# SAM9X60D1G_SOM register map
Vendor: Microchip Technology; Series: SAM9X6; File version: 0
Registers are 32-bit, read-write, reset 0x0 unless marked. A register's access mark holds for its fields unless they carry their own. Offsets are from the block's base; [hi:lo] are bit positions; {n}, {i} and the like mark numbered series.

## MPDDRC — AHB Multiport DDR-SDRAM Controller
Base 0xFFFFE800
0x00 MR — Mode Register
  [2:0] MODE — MPDDRC Command Mode
    0=NORMAL_CMD (Normal Mode. Any access to the MPDDRC is decoded normally. To activate this mode, the command must be followed by a write to the DDR-SDRAM.); 1=NOP_CMD (The MPDDRC issues a NOP command when the DDR-SDRAM device is accessed regardless of the cycle. To activate this mode, the command must be followed by a write to the DDR-SDRAM.); 2=PRCGALL_CMD (The MPDDRC issues the All Banks Precharge command when the DDR-SDRAM device is accessed regardless of the cycle. To activate this mode, the command must be followed by a write to the SDRAM.); 3=LMR_CMD (The MPDDRC issues a Load Mode Register command when the DDR-SDRAM device is accessed regardless of the cycle. To activate this mode, the command must be followed by a write to the DDR-SDRAM.); 4=RFSH_CMD (The MPDDRC issues an Autorefresh command when the DDR-SDRAM device is accessed regardless of the cycle. Previously, an All Banks Precharge command must be issued. To activate this mode, the command must be followed by a write to the DDR-SDRAM.); 5=EXT_LMR_CMD (The MPDDRC issues an Extended Load Mode Register command when the SDRAM device is accessed regardless of the cycle. To activate this mode, the command must be followed by a write to the DDR-SDRAM. The write in the DDR-SDRAM must be done in the appropriate bank.); 6=DEEP_MD (Deep Power mode: Access to Deep Powerdown mode)
0x04 RTR — Refresh Timer Register
  [11:0] COUNT — MPDDRC Refresh Timer Count
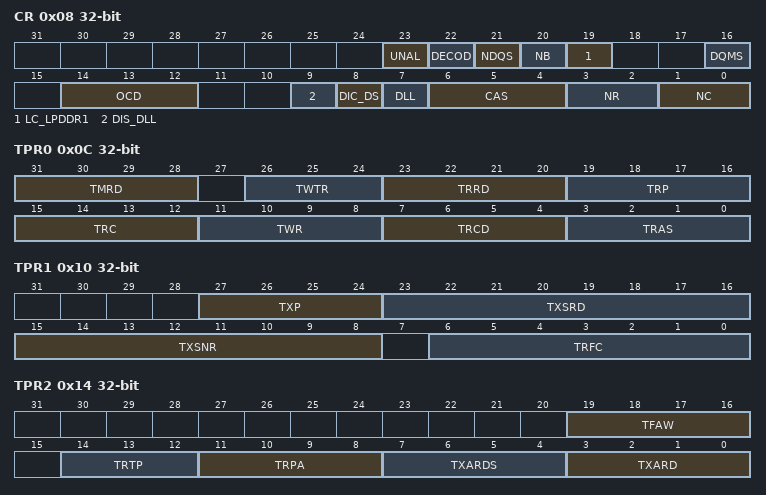
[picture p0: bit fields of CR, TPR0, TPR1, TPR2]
0x08 CR — Configuration Register
  [23] UNAL — This bit must always be written to 1
  [22] DECOD — Type of Decoding
    0=SEQUENTIAL (Method for address mapping where banks alternate at each last DDR-SDRAM page of the current bank.); 1=INTERLEAVED (Method for address mapping where banks alternate at each DDR-SDRAM end of page of the current bank.)
  [21] NDQS — Not DQS.
    0=ENABLED ('Not DQS' is enabled.); 1=DISABLED ('Not DQS' is disabled.)
  [20] NB — Number of Banks
    0=_4_BANKS (4-bank memory devices); 1=_8_BANKS (8 banks. Only possible when using DDR2-SDRAM devices.)
  [19] LC_LPDDR1 — Low-cost Low-power DDR1
    0=NOT_2_BANKS (Any type of memory devices except of low cost, low density Low Power DDR1.); 1=_2_BANKS_LPDDR1 (Low-cost and low-density low-power DDR1. These devices have a density of 32 Mbits and are organized as two internal banks. To use this feature, the user has to define the type of memory and the data bus width (see Section 8.8 'MPDDRC Memory Device Register'). The 16-bit memory device is organized as 2 banks, 9 columns and 11 rows.)
  [16] DQMS — Mask Data is Shared
    0=NOT_SHARED (DQM is not shared with another controller); 1=SHARED (DQM is shared with another controller)
  [14:12] OCD — Off-chip Driver
    0=DDR2_EXITCALIB (Exit from OCD Calibration mode and maintain settings); 7=DDR2_DEFAULT_CALIB (OCD calibration default)
  [9] DIS_DLL — DISABLE DLL
  [8] DIC_DS — Output Driver Impedance Control (Drive Strength)
    0=DDR2_NORMALSTRENGTH (Normal drive strength (DDR2)); 1=DDR2_WEAKSTRENGTH (Weak drive strength (DDR2))
  [7] DLL — Reset DLL
    0=RESET_DISABLED (Disable DLL reset); 1=RESET_ENABLED (Enable DLL reset)
  [6:4] CAS — CAS Latency
    2=DDR_CAS2 (LPDDR1 CAS Latency 2); 3=DDR_CAS3 (DDR2/LPDDR1 CAS Latency 3)
  [3:2] NR — Number of Row Bits.
    0=_11_ROW_BITS (11 bits to define the row number, up to 2048 rows); 1=_12_ROW_BITS (12 bits to define the row number, up to 4096 rows); 2=_13_ROW_BITS (13 bits to define the row number, up to 8192 rows); 3=_14_ROW_BITS (14 bits to define the row number, up to 16384 rows)
  [1:0] NC — Number of Column Bits
    0=DDR9_MDDR8_COL_BITS (9 bits to define the column number, up to 512 columns, for DDR2-SDRAM 8 bits to define the column number, up to 256 columns, for LPDDR1-SDRAM); 1=DDR10_MDDR9_COL_BITS (10 bits to define the column number, up to 1024 columns, for DDR2-SDRAM 9 bits to define the column number, up to 512 columns, for LPDDR1-SDRAM); 2=DDR11_MDDR10_COL_BITS (11 bits to define the column number, up to 2048 columns, for DDR2-SDRAM 10 bits to define the column number, up to 1024 columns, for LPDDR1-SDRAM); 3=DDR12_MDDR11_COL_BITS (12 bits to define the column number, up to 4096 columns, for DDR2-SDRAM 11 bits to define the column number, up to 2048 columns, for LPDDR1-SDRAM)
0x0C TPR0 — Timing Parameter 0 Register
  [31:28] TMRD — Load Mode Register Command to Activate or Refresh Command
  [26:24] TWTR — Internal Write to Read Delay
  [23:20] TRRD — Active BankA to Active BankB
  [19:16] TRP — Row Precharge Delay
  [15:12] TRC — Row Cycle Delay
  [11:8] TWR — Write Recovery Delay
  [7:4] TRCD — Row to Column Delay
  [3:0] TRAS — Active to Precharge Delay
0x10 TPR1 — Timing Parameter 1 Register
  [27:24] TXP — Exit Powerdown Delay to First Command
  [23:16] TXSRD — Exit Self-refresh Delay to Read Command
  [15:8] TXSNR — Exit Self-refresh Delay to Non-Read Command
  [6:0] TRFC — Row Refresh Cycle
0x14 TPR2 — Timing Parameter 2 Register
  [19:16] TFAW — Four Active Windows
  [14:12] TRTP — Read to Precharge
  [11:8] TRPA — Row Precharge All Delay
  [7:4] TXARDS — Exit Active Power Down Delay to Read Command in Mode 'Slow Exit'
  [3:0] TXARD — Exit Active Power Down Delay to Read Command in Mode 'Fast Exit'
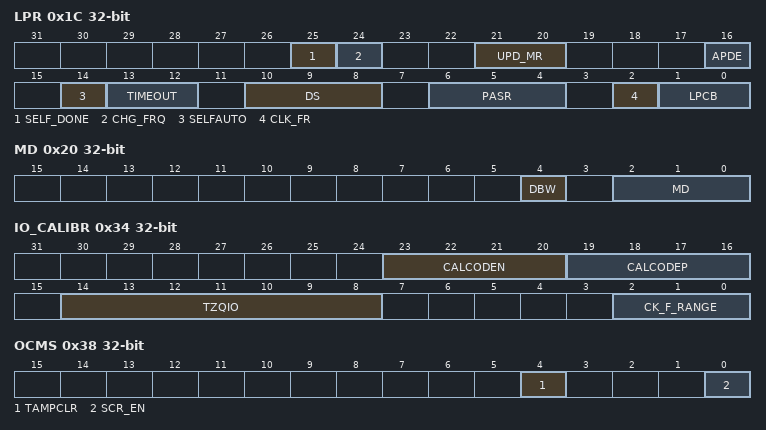
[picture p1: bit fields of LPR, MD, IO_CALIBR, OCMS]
0x1C LPR — Low-Power Register
  [25] SELF_DONE — Self-refresh is Done (read-only)
  [24] CHG_FRQ — Change Clock Frequency During Self-refresh Mode
  [21:20] UPD_MR — Update Load Mode Register and Extended Mode Register
    0=NO_UPDATE (Update of Load Mode and Extended Mode registers is disabled.); 1=UPDATE_SHAREDBUS (MPDDRC shares an external bus. Automatic update is done during a refresh command and a pending read or write access in the SDRAM device.); 2=UPDATE_NOSHAREDBUS (MPDDRC does not share an external bus. Automatic update is done before entering Self-refresh mode.)
  [16] APDE — Active Power Down Exit Time
    0=DDR2_FAST_EXIT (Fast Exit from Power Down. DDR2-SDRAM devices only.); 1=DDR2_SLOW_EXIT (Slow Exit from Power Down. DDR2-SDRAM devices only.)
  [14] SELFAUTO — Self-refresh Exit Autorefresh
  [13:12] TIMEOUT — Time Between Last Transfer and Low-Power Mode
    0=NONE (SDRAM Low-power mode is activated immediately after the end of the last transfer.); 1=DELAY_64_CLK (SDRAM Low-power mode is activated 64 clock cycles after the end of the last transfer.); 2=DELAY_128_CLK (SDRAM Low-power mode is activated 128 clock cycles after the end of the last transfer.)
  [10:8] DS — Drive Strength
    0=DS_FULL (Full drive strength); 1=DS_HALF (Half drive strength); 2=DS_QUARTER (Quarter drive strength); 3=DS_OCTANT (Octant drive strength)
  [6:4] PASR — Partial Array Self-refresh
  [2] CLK_FR — Clock Frozen Command Bit
    0=DISABLED (Clock(s) is/are not frozen.); 1=ENABLED (Clock(s) is/are frozen.)
  [1:0] LPCB — Low-power Command Bit
    0=NOLOWPOWER (Low-power feature is inhibited. No Powerdown, Self-refresh and Deep power modes are issued to the DDR-SDRAM device.); 1=SELFREFRESH (The MPDDRC issues a self-refresh command to the DDR-SDRAM device, the clock(s) is/are deactivated and the CKE signal is set low. The DDR-SDRAM device leaves the Self-refresh mode when accessed and reenters it after the access.); 2=POWERDOWN (The MPDDRC issues a Powerdown command to the DDR-SDRAM device after each access, the CKE signal is set low. The DDR-SDRAM device leaves the Powerdown mode when accessed and reenters it after the access.); 3=DEEPPOWERDOWN (The MPDDRC issues a Deep Powerdown command to the low-power DDR-SDRAM device.)
0x20 MD — Memory Device Register
  [4] DBW — Data Bus Width
    1=DBW_16_BITS (Data bus width is 16 bits.)
  [2:0] MD — Memory Device
    3=LPDDR_SDRAM (Low-power DDR1-SDRAM); 6=DDR2_SDRAM
0x34 IO_CALIBR — I/O Calibration Register
  [23:20] CALCODEN — Number of N-type Transistors (read-only)
  [19:16] CALCODEP — Number of P-type Transistors (read-only)
  [14:8] TZQIO — IO Calibration
  [2:0] CK_F_RANGE — DDRCK Maximum Clock Frequency Range Indicator
0x38 OCMS
  [4] TAMPCLR — Tamper Clear Enable
  [0] SCR_EN — Scrambling Enable
0x3C OCMS_KEY1 wo
  [31:0] KEY1 — Off-chip Memory Scrambling (OCMS) Key Part 1
0x40 OCMS_KEY2 wo
  [31:0] KEY2 — Off-chip Memory Scrambling (OCMS) Key Part 2
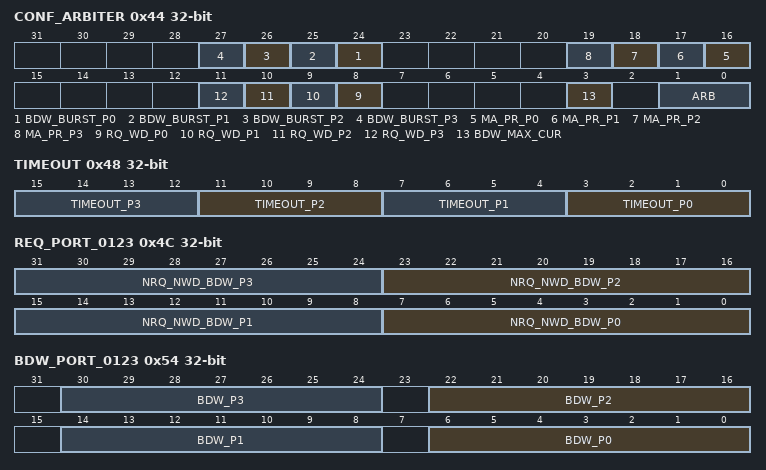
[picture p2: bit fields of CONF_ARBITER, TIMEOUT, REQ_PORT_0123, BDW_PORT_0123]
0x44 CONF_ARBITER — Configuration Arbiter Register
  [n+24] BDW_BURST_P{n} (n=0..3) — Bandwidth Arbitration Mode on Port X
  [n+16] MA_PR_P{n} (n=0..3) — Master or Software Provide Information
  [n+8] RQ_WD_P{n} (n=0..3) — Request or Word from Port X
  [3] BDW_MAX_CUR — Bandwidth Max or Current
  [1:0] ARB — Type of Arbitration
    0=ROUND (Round-Robin Policy); 1=NB_REQUEST (Request Policy); 2=BANDWIDTH (Bandwidth Policy); 3=LQOS (Quality of Service Policy)
0x48 TIMEOUT
  [4n+3:4n] TIMEOUT_P{n} (n=0..3) — Timeout for Ports 0, 1, 2, 3
0x4C REQ_PORT_0123 — Request Port 0-1-2-3 Register
  [8n+7:8n] NRQ_NWD_BDW_P{n} (n=0..3) — Number of Requests, Number of Words or Bandwidth Allocation from Port 0-1-2-3
0x54 BDW_PORT_0123 ro — Current/Maximum Bandwidth Port 0-1-2-3 Register
  [8n+6:8n] BDW_P{n} (n=0..3) — Current/Maximum Bandwidth from Port 0-1-2-3
0x5C RD_DATA_PATH — Read Data Path Register
  [1:0] SHIFT_SAMPLING — Shift Sampling Point of Data
    0=NO_SHIFT (Initial sampling point.); 1=SHIFT_ONE_CYCLE (Sampling point is shifted by one cycle.); 2=SHIFT_TWO_CYCLES (Sampling point is shifted by two cycles.); 3=SHIFT_THREE_CYCLES (Not applicable for DDR2 and LPDDR1 devices.)
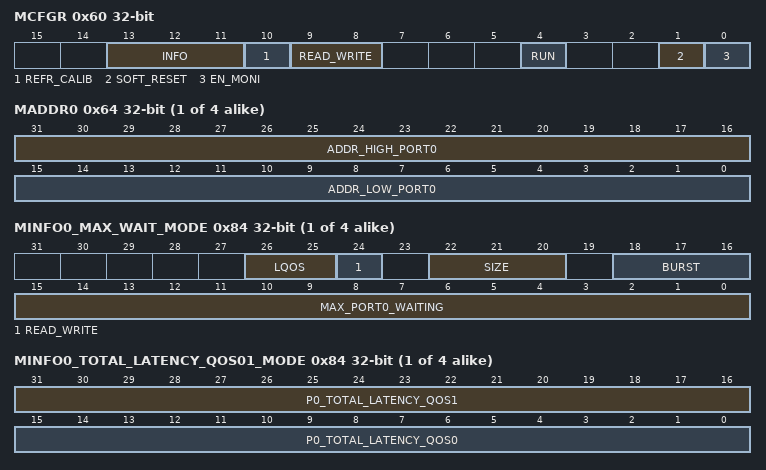
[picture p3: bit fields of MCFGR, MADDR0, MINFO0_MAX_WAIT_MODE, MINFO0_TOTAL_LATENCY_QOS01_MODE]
0x60 MCFGR — Monitor Configuration Register
  [13:11] INFO — Information Type
    0=MAX_WAIT (Information concerning the transfer with the longest waiting time); 1=NB_TRANSFERS (Number of transfers on the port); 2=TOTAL_LATENCY (Total latency on the port); 4=MAX_WAIT_QOS01 (Information concerning the transfer with the longest waiting time, depending on QOS values (0 and 1)); 5=MAX_WAIT_QOS23 (Information concerning the transfer with the longest waiting time, depending on QOS values (2 and 3))
  [10] REFR_CALIB — Refresh Calibration
  [9:8] READ_WRITE — Read/Write Access
    0=TRIG_RD_WR (Read and Write accesses are triggered.); 1=TRIG_WR (Only Write accesses are triggered.); 2=TRIG_RD (Only Read accesses are triggered.)
  [4] RUN — Control Monitor
  [1] SOFT_RESET
  [0] EN_MONI — Enable Monitor
{0x64+4i} MADDR{i} (i=0..3) — Monitor Address High/Low Port {i} Register
  [31:16] ADDR_HIGH_PORT{i} — Address High on Port {i}
  [15:0] ADDR_LOW_PORT{i} — Address Low on Port {i}
{0x84+4i} MINFO{i}_MAX_WAIT_MODE ro (i=0..3) — Monitor Information Port {i} Register
  [26:25] LQOS — Value of Quality Of Service on Port {i}
    0=BACKGROUND (Background transfers); 1=BANDWIDTH (Bandwidth sensitive); 2=SENSITIVE_LAT (Latency sensitive); 3=CRITICAL_LAT (Latency critical)
  [24] READ_WRITE — Read or Write Access on Port {i}
  [22:20] SIZE — Transfer Size on Port {i}
    0=_8BITS (Byte transfer); 1=_16BITS (Halfword transfer); 2=_32BITS (Word transfer); 3=_64BITS (Dword transfer)
  [18:16] BURST — Type of Burst on Port {i}
    0=SINGLE (Single transfer); 1=INCR (Incrementing burst of unspecified length); 2=WRAP4 (4-beat wrapping burst); 3=INCR4 (4-beat incrementing burst); 4=WRAP8 (8-beat wrapping burst); 5=INCR8 (8-beat incrementing burst); 6=WRAP16 (16-beat wrapping burst); 7=INCR16 (16-beat incrementing burst)
  [15:0] MAX_PORT{i}_WAITING — Address High on Port {i}
{0x84+4i} MINFO{i}_NB_TRANSFERS_MODE ro (alternate view of MINFO{i}_MAX_WAIT_MODE) (i=0..3) — Monitor Information Port {i} Register
  [31:0] P{i}_NB_TRANSFERS — Number of Transfers on Port {i}
{0x84+4i} MINFO{i}_TOTAL_LATENCY_MODE ro (alternate view of MINFO{i}_MAX_WAIT_MODE) (i=0..3) — Monitor Information Port {i} Register
  [31:0] P{i}_TOTAL_LATENCY — Total Latency on Port {i}
{0x84+4i} MINFO{i}_TOTAL_LATENCY_QOS01_MODE ro (alternate view of MINFO{i}_MAX_WAIT_MODE) (i=0..3) — Monitor Information Port {i} Register
  [31:16] P{i}_TOTAL_LATENCY_QOS1 — Total Latency on Port 1 when value of qos is 1
  [15:0] P{i}_TOTAL_LATENCY_QOS0 — Total Latency on Port 0 when value of qos is 0
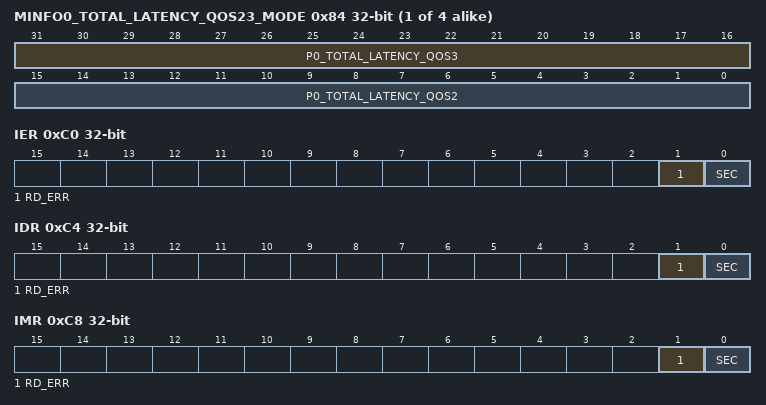
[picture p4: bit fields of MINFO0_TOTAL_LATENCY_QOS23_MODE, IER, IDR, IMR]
{0x84+4i} MINFO{i}_TOTAL_LATENCY_QOS23_MODE ro (alternate view of MINFO{i}_MAX_WAIT_MODE) (i=0..3) — Monitor Information Port {i} Register
  [31:16] P{i}_TOTAL_LATENCY_QOS3 — Total Latency on Port 3 when value of qos is 3
  [15:0] P{i}_TOTAL_LATENCY_QOS2 — Total Latency on Port 2 when value of qos is 2
0xC0 IER wo — Interrupt Enable Register
  [1] RD_ERR — Read Error Interrupt Enable
  [0] SEC — Security and /or Safety Interrupt Enable
0xC4 IDR wo — Interrupt Disable Register
  [1] RD_ERR — Read Error Interrupt Disable
  [0] SEC — Security and /or Safety Interrupt Disable
0xC8 IMR ro — Interrupt Mask Register
  [1] RD_ERR — Read Error Interrupt Mask
  [0] SEC — Security and /or Safety Interrupt Mask
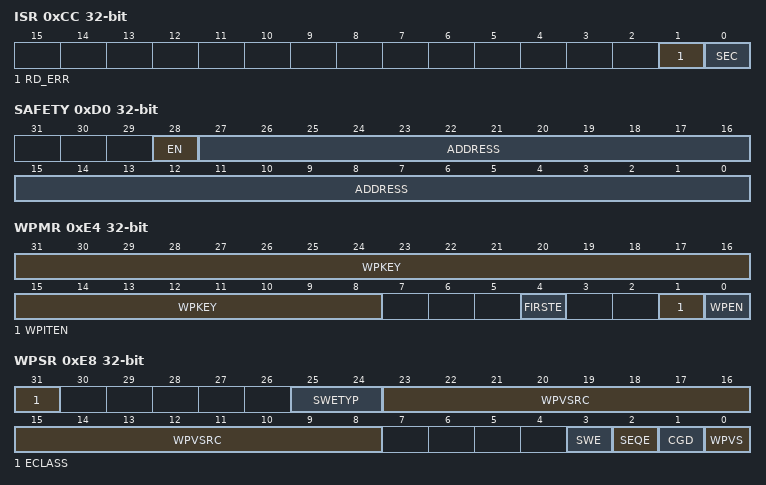
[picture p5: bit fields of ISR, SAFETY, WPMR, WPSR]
0xCC ISR ro — Interrupt Status Register
  [1] RD_ERR — Read Error
  [0] SEC — Security and /or Safety Event
0xD0 SAFETY
  [28] EN — Enable Periodic Check of Memory Device
  [27:0] ADDRESS — Memory Device Address
0xE4 WPMR — Write Protection Mode Register
  [31:8] WPKEY — Write Protection Key
    0x444452=PASSWD (Writing any other value in this field aborts the write operation of the WPEN and WPITEN bits. Always reads as 0.)
  [4] FIRSTE — First Error Report Enable
  [1] WPITEN — Write Protection Interruption Enable
  [0] WPEN — Write Protection Enable
0xE8 WPSR ro — Write Protection Status Register
  [31] ECLASS — Software Error Class (cleared on read)
    0=WARNING (An abnormal access that does not affect system functionality is performed.); 1=ERROR (An access is performed into some registers after memory device initialization sequence.)
  [25:24] SWETYP — Software Error Type (cleared on read)
    0=READ_WO (A write-only register has been read (warning).); 1=WRITE_RO (MPDDRC is enabled and a write access has been performed on a read-only register (warning).); 2=UNDEF_RW (Access to an undefined address (warning).); 3=W_AFTER_INIT (Abnormal use of MPDDRC user interface when memory device is already configured and initialized, i.e., if MPDDRC_RTR.COUNT > 0 (error).)
  [23:8] WPVSRC — Write Protection Violation Source
  [3] SWE — Software Control Error (cleared on read)
  [2] SEQE — Internal Sequencer Error (cleared on read)
  [1] CGD — Clock Glitch Detected (cleared on read)
  [0] WPVS — Write Protection Enable
